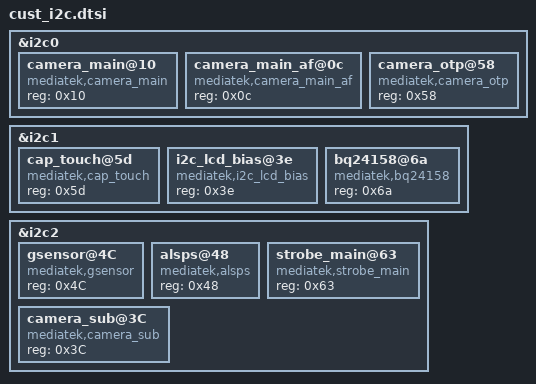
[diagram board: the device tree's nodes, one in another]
/*
 * Generated by MTK SP Drv_CodeGen Version 03.13.6  for MT6735. Copyright MediaTek Inc. (C) 2013.
 * Thu Jun  4 21:49:55 2015
 * Do Not Modify the File.
 */

/*************************
 * I2C dtsi file
*************************/

&i2c0 {
	camera_main@10 {
		compatible = "mediatek,camera_main";
		reg = <0x10>;
	};

	camera_main_af@0c {
		compatible = "mediatek,camera_main_af";
		reg = <0x0c>;
	};

	camera_otp@58 {
		compatible = "mediatek,camera_otp";
		reg = <0x58>;
	};

};

&i2c1 {
	cap_touch@5d {
		compatible = "mediatek,cap_touch";
		reg = <0x5d>;
	};

	i2c_lcd_bias@3e {
		compatible = "mediatek,i2c_lcd_bias";
		reg = <0x3e>;
	};

	bq24158@6a {
		compatible = "mediatek,bq24158";
		reg = <0x6a>;
	};

};

&i2c2 {
	gsensor@4C {
		compatible = "mediatek,gsensor";
		reg = <0x4C>;
	};

	alsps@48 {
		compatible = "mediatek,alsps";
		reg = <0x48>;
	};

	strobe_main@63 {
		compatible = "mediatek,strobe_main";
		reg = <0x63>;
	};

	camera_sub@3C {
		compatible = "mediatek,camera_sub";
		reg = <0x3C>;
	};
};
